# F28x7x_sdfm_regs register map
Vendor: Texas Instruments
Peripheral module from a debugger description file (folder C2000).
Address unit: 16 bits
Registers are 16-bit, read-write, no defined reset value unless marked. A register's access mark holds for its fields unless they carry their own. Offsets are as the file gives them; lines under a group give offsets from that group; [hi:lo] are bit positions; {n}, {i} and the like mark numbered series; 'fields as' and 'values as' point back to an identical list; <NAME> marks a mode.

## SDFM_REGS — SDFM Registers
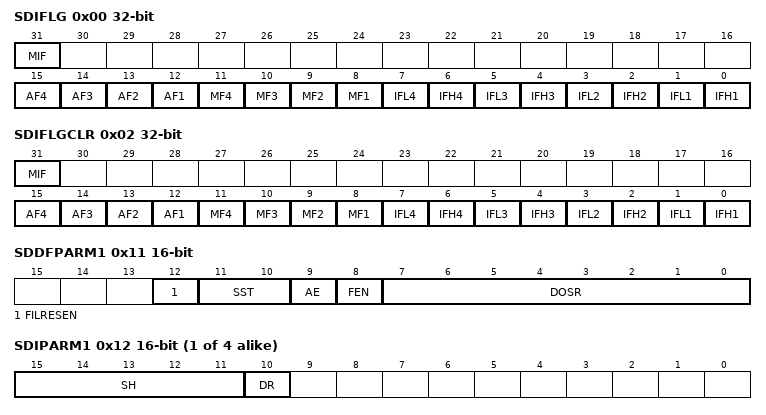
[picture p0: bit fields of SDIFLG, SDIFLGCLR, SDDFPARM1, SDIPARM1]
0x00 SDIFLG 32-bit ro — Interrupt Flag Register
  [31] MIF — Master Interrupt Flag
  [n+11] AF{n} (n=1..4) — Acknowledge flag for Filter {n}
  [n+7] MF{n} (n=1..4) — Modulator Failure for Filter {n}
  [2n-1] IFL{n} (n=1..4) — Low-Level Interrupt flag Filter {n}
  [2n-2] IFH{n} (n=1..4) — High-level Interrupt flag Filter {n}
0x02 SDIFLGCLR 32-bit access not given — Interrupt Flag Clear Register
  [31] MIF — Master Interrupt Flag (access R=0/W=1)
  [n+11] AF{n} (n=1..4) — Acknowledge flag for Filter {n} (access R=0/W=1)
  [n+7] MF{n} (n=1..4) — Modulator Failure for Filter {n} (access R=0/W=1)
  [2n-1] IFL{n} (n=1..4) — Low-Level Interrupt flag Filter {n} (access R=0/W=1)
  [2n-2] IFH{n} (n=1..4) — High-level Interrupt flag Filter {n} (access R=0/W=1)
0x04 SDCTL — SD Control Register
  [13] MIE — Master Interrupt enable
0x06 SDMFILEN — SD Master Filter Enable
  [11] MFE — Master Filter Enable.
0x10 SDCTLPARM1 — Control Parameter Register for Ch1
  [1:0] MOD — Delta-Sigma Modulator mode
0x11 SDDFPARM1 — Data Filter Parameter Register for Ch1
  [12] FILRESEN — Data FILTER Reset Enable
  [11:10] SST — Data Filter Structure (DataFast/1/2/3)
  [9] AE — Ack Enable
  [8] FEN — Filter Enable
  [7:0] DOSR — Data Filter Oversample Ratio= DOSR+1
{0x2+0x10*i} SDIPARM{i} (i=1..4) — Integer Parameter Register for Ch{i}
  [15:11] SH — Shift Control (# bits to shift in 16b mode)
  [10] DR — Data Representation (0/1 = 16/32b 2's complement)
{0x3+0x10*i} SDCMPH{i} (i=1..4) — High-level Threshold Register for Ch{i}
  [14:0] HLT — High-level threshold for the comparator filter output.
{0x4+0x10*i} SDCMPL{i} (i=1..4) — Low-level Threshold Register for Ch{i}
  [14:0] LLT — Low-level threshold for the comparator filter output.
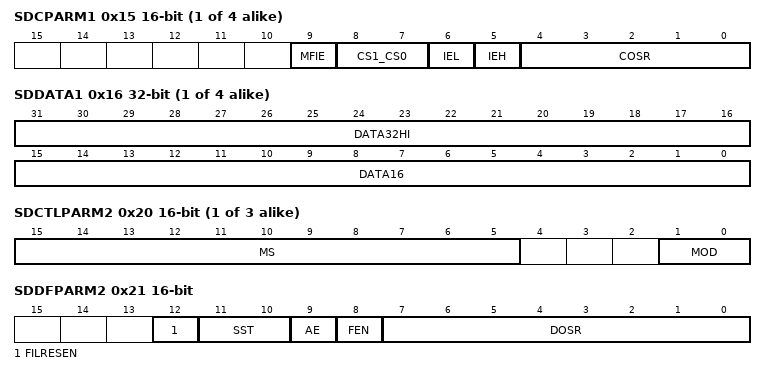
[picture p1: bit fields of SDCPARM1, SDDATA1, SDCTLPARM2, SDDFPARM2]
{0x5+0x10*i} SDCPARM{i} (i=1..4) — Comparator Parameter Register for Ch{i}
  [9] MFIE — Modulator Failure Interrupt enable
  [8:7] CS1_CS0 — Comparator filter structure (Sincfast/Sinc1/Sinc2/Sinc3
  [6] IEL — Low-level interrupt enable
  [5] IEH — High-level interrupt enable
  [4:0] COSR — Comparator Oversample Ratio = COSR + 1
{0x6+0x10*i} SDDATA{i} 32-bit ro (i=1..4) — Filter Data Register (16 or 32bit) for Ch{i}
  [31:16] DATA32HI — Hi-order 16b in 32b mode
  [15:0] DATA16 — 16-bit Data in 16b mode, Lo-order 16b in 32b mode
{0x0+0x10*i} SDCTLPARM{i} access per field (i=2..4) — Control Parameter Register for Ch{i}
  [15:5] MS ro — Manchester Status
  [1:0] MOD rw — Delta-Sigma Modulator mode
0x21 SDDFPARM2 — Data Filter Parameter Register for Ch2
  [12] FILRESEN — Data FILTER Reset Enable
  [11:10] SST — Data Filter Structure (SincFast/1/2/3)
  [9] AE — Ack Enable
  [8] FEN — Filter Enable
  [7:0] DOSR — Data Filter Oversample Ratio= DOSR+1
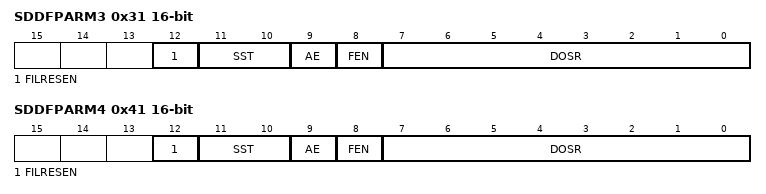
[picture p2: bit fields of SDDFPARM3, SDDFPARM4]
0x31 SDDFPARM3 — Data Filter Parameter Register for Ch3
  [12] FILRESEN — Data FILTER Reset Enable
  [11:10] SST — Data filter structure (SincFast/1/2/3)
  [9] AE — Ack Enable
  [8] FEN — Filter Enable
  [7:0] DOSR — Data Filter Oversample Ratio= DOSR+1
0x41 SDDFPARM4 — Data Filter Parameter Register for Ch4
  [12] FILRESEN — SINC FILTER Reset Enable
  [11:10] SST — Data filter structure (SincFast/1/2/3)
  [9] AE — Ack Enable
  [8] FEN — Filter Enable
  [7:0] DOSR — SINC Filter Oversample Ratio= DOSR+1
